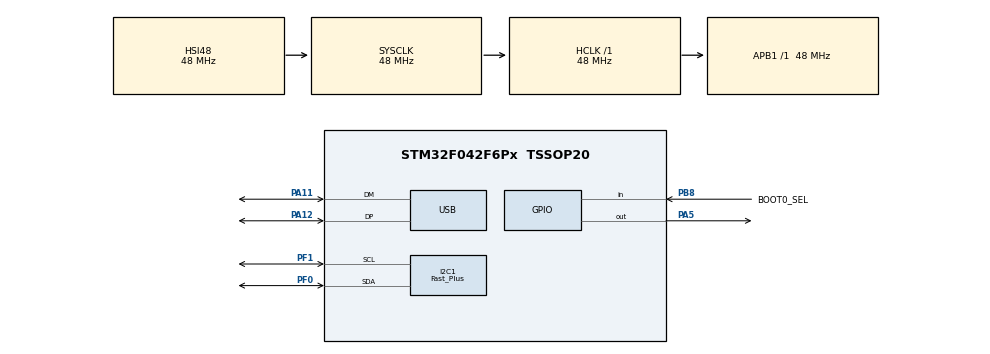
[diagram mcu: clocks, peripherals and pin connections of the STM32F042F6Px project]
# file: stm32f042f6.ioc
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I2C1.I2C_Fall_Time=10
I2C1.I2C_Rise_Time=10
I2C1.I2C_Speed_Mode=I2C_Fast_Plus
I2C1.Speed=400
I2C1.Timing=0x00201953
Mcu.Family=STM32F0
Mcu.Name=STM32F042F6Px
Mcu.Package=TSSOP20
NVIC.USB_IRQn=true\:0\:0\:false\:false\:true\:false
PA11.Mode=Device
PA11.Signal=USB_DM
PA12.Mode=Device
PA12.Signal=USB_DP
PA13.Mode=Serial_Wire
PA13.Signal=SYS_SWDIO
PA14.Mode=Serial_Wire
PA14.Signal=SYS_SWCLK
PA5.Signal=GPIO_Output
PB8.GPIO_Label=BOOT0_SEL
PB8.Signal=GPIO_Input
PF0-OSC_IN.Mode=I2C
PF0-OSC_IN.Signal=I2C1_SDA
PF1-OSC_OUT.Mode=I2C
PF1-OSC_OUT.Signal=I2C1_SCL
ProjectManager.HeapSize=0x200
ProjectManager.StackSize=0x300
ProjectManager.TargetToolchain=TrueSTUDIO
RCC.AHBFreq_Value=48000000
RCC.APB1Freq_Value=48000000
RCC.APB1TimFreq_Value=48000000
RCC.HCLKFreq_Value=48000000
RCC.I2c1ClockSelection=RCC_I2C1CLKSOURCE_SYSCLK
RCC.SYSCLKFreq_VALUE=48000000
RCC.SYSCLKSource=RCC_SYSCLKSOURCE_HSI48
USB_DEVICE.CLASS_NAME_FS=CDC
USB_DEVICE.USBD_SELF_POWERED=0
USB_DEVICE.VirtualMode=Cdc
USB_DEVICE.VirtualModeFS=Cdc_FS
VP_SYS_VS_PINREMAP.Mode=PINREMAP
VP_USB_DEVICE_VS_USB_DEVICE_CDC_FS.Mode=CDC_FS
board=custom

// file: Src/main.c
/**
  ******************************************************************************
  * @file           : main.c
  * @brief          : Main program body
  ******************************************************************************
  * This notice applies to any and all portions of this file
  * that are not between comment pairs USER CODE BEGIN and
  * USER CODE END. Other portions of this file, whether
  * inserted by the user or by software development tools
  * are owned by their respective copyright owners.
  *
  * Copyright (c) 2019 STMicroelectronics International N.V.
  * All rights reserved.
  *
  * Redistribution and use in source and binary forms, with or without
  * modification, are permitted, provided that the following conditions are met:
  *
  * 1. Redistribution of source code must retain the above copyright notice,
  *    this list of conditions and the following disclaimer.
  * 2. Redistributions in binary form must reproduce the above copyright notice,
  *    this list of conditions and the following disclaimer in the documentation
  *    and/or other materials provided with the distribution.
  * 3. Neither the name of STMicroelectronics nor the names of other
  *    contributors to this software may be used to endorse or promote products
  *    derived from this software without specific written permission.
  * 4. This software, including modifications and/or derivative works of this
  *    software, must execute solely and exclusively on microcontroller or
  *    microprocessor devices manufactured by or for STMicroelectronics.
  * 5. Redistribution and use of this software other than as permitted under
  *    this license is void and will automatically terminate your rights under
  *    this license.
  *
  * THIS SOFTWARE IS PROVIDED BY STMICROELECTRONICS AND CONTRIBUTORS "AS IS"
  * AND ANY EXPRESS, IMPLIED OR STATUTORY WARRANTIES, INCLUDING, BUT NOT
  * LIMITED TO, THE IMPLIED WARRANTIES OF MERCHANTABILITY, FITNESS FOR A
  * PARTICULAR PURPOSE AND NON-INFRINGEMENT OF THIRD PARTY INTELLECTUAL PROPERTY
  * RIGHTS ARE DISCLAIMED TO THE FULLEST EXTENT PERMITTED BY LAW. IN NO EVENT
  * SHALL STMICROELECTRONICS OR CONTRIBUTORS BE LIABLE FOR ANY DIRECT, INDIRECT,
  * INCIDENTAL, SPECIAL, EXEMPLARY, OR CONSEQUENTIAL DAMAGES (INCLUDING, BUT NOT
  * LIMITED TO, PROCUREMENT OF SUBSTITUTE GOODS OR SERVICES; LOSS OF USE, DATA,
  * OR PROFITS; OR BUSINESS INTERRUPTION) HOWEVER CAUSED AND ON ANY THEORY OF
  * LIABILITY, WHETHER IN CONTRACT, STRICT LIABILITY, OR TORT (INCLUDING
  * NEGLIGENCE OR OTHERWISE) ARISING IN ANY WAY OUT OF THE USE OF THIS SOFTWARE,
  * EVEN IF ADVISED OF THE POSSIBILITY OF SUCH DAMAGE.
  *
  ******************************************************************************
  */
#include "main.h"
#include "stm32f0xx_hal.h"
#include "i2c.h"
#include "usb_device.h"
#include "gpio.h"

/* USER CODE BEGIN PV */
/* Private variables ---------------------------------------------------------*/

/* USER CODE END PV */

void SystemClock_Config(void);

/* USER CODE BEGIN PFP */
/* Private function prototypes -----------------------------------------------*/

/* USER CODE END PFP */

int main(void)
{

  /* MCU Configuration----------------------------------------------------------*/

  /* Reset of all peripherals, Initializes the Flash interface and the Systick. */
  HAL_Init();

  /* Configure the system clock */
  SystemClock_Config();

  /* Initialize all configured peripherals */
  MX_GPIO_Init();
  MX_I2C1_Init();
  MX_USB_DEVICE_Init();
  /* USER CODE BEGIN 2 */
  main_loop();
  /* USER CODE END 2 */

  /* Infinite loop */
  while (1)
  {

  }

}

void SystemClock_Config(void)
{

  RCC_OscInitTypeDef RCC_OscInitStruct;
  RCC_ClkInitTypeDef RCC_ClkInitStruct;
  RCC_PeriphCLKInitTypeDef PeriphClkInit;

    /**Initializes the CPU, AHB and APB busses clocks
    */
  RCC_OscInitStruct.OscillatorType = RCC_OSCILLATORTYPE_HSI48;
  RCC_OscInitStruct.HSI48State = RCC_HSI48_ON;
  RCC_OscInitStruct.PLL.PLLState = RCC_PLL_NONE;
  if (HAL_RCC_OscConfig(&RCC_OscInitStruct) != HAL_OK)
  {
    _Error_Handler(__FILE__, __LINE__);
  }

    /**Initializes the CPU, AHB and APB busses clocks
    */
  RCC_ClkInitStruct.ClockType = RCC_CLOCKTYPE_HCLK|RCC_CLOCKTYPE_SYSCLK
                              |RCC_CLOCKTYPE_PCLK1;
  RCC_ClkInitStruct.SYSCLKSource = RCC_SYSCLKSOURCE_HSI48;
  RCC_ClkInitStruct.AHBCLKDivider = RCC_SYSCLK_DIV1;
  RCC_ClkInitStruct.APB1CLKDivider = RCC_HCLK_DIV1;

  if (HAL_RCC_ClockConfig(&RCC_ClkInitStruct, FLASH_LATENCY_1) != HAL_OK)
  {
    _Error_Handler(__FILE__, __LINE__);
  }

  PeriphClkInit.PeriphClockSelection = RCC_PERIPHCLK_USB|RCC_PERIPHCLK_I2C1;
  PeriphClkInit.I2c1ClockSelection = RCC_I2C1CLKSOURCE_SYSCLK;
  PeriphClkInit.UsbClockSelection = RCC_USBCLKSOURCE_HSI48;

  if (HAL_RCCEx_PeriphCLKConfig(&PeriphClkInit) != HAL_OK)
  {
    _Error_Handler(__FILE__, __LINE__);
  }

    /**Configure the Systick interrupt time
    */
  HAL_SYSTICK_Config(HAL_RCC_GetHCLKFreq()/1000);

    /**Configure the Systick
    */
  HAL_SYSTICK_CLKSourceConfig(SYSTICK_CLKSOURCE_HCLK);

  /* SysTick_IRQn interrupt configuration */
  HAL_NVIC_SetPriority(SysTick_IRQn, 0, 0);
}

void _Error_Handler(char *file, int line)
{
  while(1)
  {
  }
}

/************************ (C) COPYRIGHT STMicroelectronics *****END OF FILE****/
